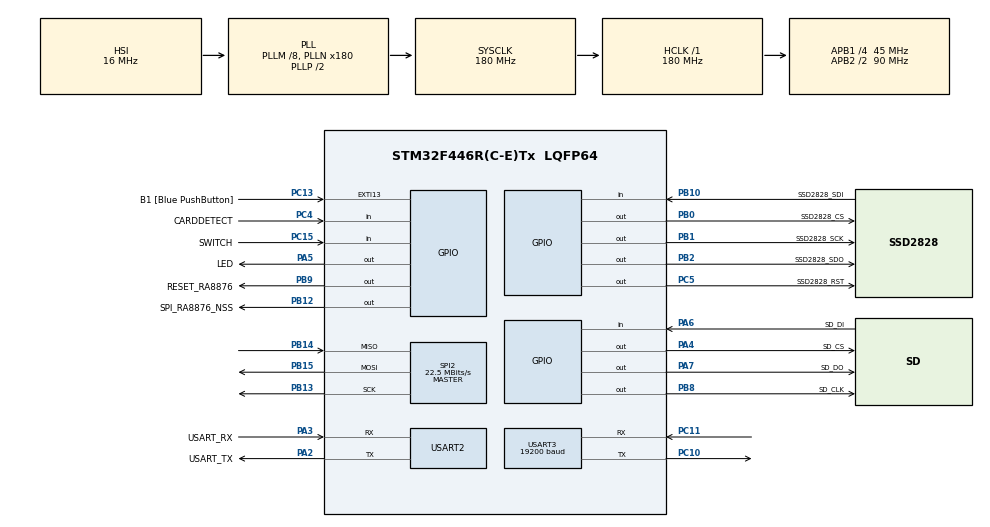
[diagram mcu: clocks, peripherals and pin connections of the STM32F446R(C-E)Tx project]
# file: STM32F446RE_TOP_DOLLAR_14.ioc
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Mcu.Family=STM32F4
Mcu.Name=STM32F446R(C-E)Tx
Mcu.Package=LQFP64
NVIC.PriorityGroup=NVIC_PRIORITYGROUP_0
NVIC.USART3_IRQn=true\:0\:0\:false\:false\:true\:true\:true\:true
PA13.GPIO_Label=TMS
PA13.Mode=Serial_Wire
PA13.Signal=SYS_JTMS-SWDIO
PA14.GPIO_Label=TCK
PA14.Mode=Serial_Wire
PA14.Signal=SYS_JTCK-SWCLK
PA2.GPIO_Label=USART_TX
PA2.Mode=Asynchronous
PA2.Signal=USART2_TX
PA3.GPIO_Label=USART_RX
PA3.Mode=Asynchronous
PA3.Signal=USART2_RX
PA4.GPIO_Label=SD_CS
PA4.Signal=GPIO_Output
PA5.GPIO_Label=LED
PA5.Signal=GPIO_Output
PA6.GPIO_Label=SD_DI
PA6.Signal=GPIO_Input
PA7.GPIO_Label=SD_DO
PA7.Signal=GPIO_Output
PB0.GPIO_Label=SSD2828_CS
PB0.Signal=GPIO_Output
PB1.GPIO_Label=SSD2828_SCK
PB1.Signal=GPIO_Output
PB10.GPIO_Label=SSD2828_SDI
PB10.Signal=GPIO_Input
PB12.GPIO_Label=SPI_RA8876_NSS
PB12.Signal=GPIO_Output
PB13.Mode=Full_Duplex_Master
PB13.Signal=SPI2_SCK
PB14.Mode=Full_Duplex_Master
PB14.Signal=SPI2_MISO
PB15.Mode=Full_Duplex_Master
PB15.Signal=SPI2_MOSI
PB2.GPIO_Label=SSD2828_SDO
PB2.Signal=GPIO_Output
PB3.GPIO_Label=SWO
PB3.Signal=SYS_JTDO-SWO
PB8.GPIO_Label=SD_CLK
PB8.GPIO_PuPd=GPIO_PULLDOWN
PB8.Signal=GPIO_Output
PB9.GPIO_Label=RESET_RA8876
PB9.Signal=GPIO_Output
PC10.Mode=Multiprocessor_communication
PC10.Signal=USART3_TX
PC11.Mode=Multiprocessor_communication
PC11.Signal=USART3_RX
PC13.GPIO_Label=B1 [Blue PushButton]
PC13.GPIO_ModeDefaultEXTI=GPIO_MODE_IT_FALLING
PC13.Signal=GPXTI13
PC15-OSC32_OUT.GPIO_Label=SWITCH
PC15-OSC32_OUT.GPIO_PuPd=GPIO_NOPULL
PC15-OSC32_OUT.Signal=GPIO_Input
PC4.GPIO_Label=CARDDETECT
PC4.GPIO_PuPd=GPIO_PULLDOWN
PC4.Signal=GPIO_Input
PC5.GPIO_Label=SSD2828_RST
PC5.Signal=GPIO_Output
PH0-OSC_IN.Mode=HSE-External-Oscillator
PH0-OSC_IN.Signal=RCC_OSC_IN
PH1-OSC_OUT.Mode=HSE-External-Oscillator
PH1-OSC_OUT.Signal=RCC_OSC_OUT
ProjectManager.HeapSize=0x200
ProjectManager.StackSize=0x400
ProjectManager.TargetToolchain=STM32CubeIDE
RCC.48MHZClocksFreq_Value=84000000
RCC.AHBFreq_Value=180000000
RCC.APB1CLKDivider=RCC_HCLK_DIV4
RCC.APB1Freq_Value=45000000
RCC.APB1TimFreq_Value=90000000
RCC.APB2CLKDivider=RCC_HCLK_DIV2
RCC.APB2Freq_Value=90000000
RCC.APB2TimFreq_Value=180000000
RCC.CortexFreq_Value=180000000
RCC.FLatency-AdvancedSettings=FLASH_LATENCY_5
RCC.HCLKFreq_Value=180000000
RCC.HSE_VALUE=8000000
RCC.HSI_VALUE=16000000
RCC.PLLM=8
RCC.PLLN=180
RCC.SYSCLKFreq_VALUE=180000000
RCC.SYSCLKSource=RCC_SYSCLKSOURCE_PLLCLK
RCC.USBFreq_Value=180000000
RCC.VCOOutputFreq_Value=360000000
SPI2.BaudRatePrescaler=SPI_BAUDRATEPRESCALER_2
SPI2.CalculateBaudRate=22.5 MBits/s
SPI2.Direction=SPI_DIRECTION_2LINES
SPI2.Mode=SPI_MODE_MASTER
SPI2.VirtualType=VM_MASTER
USART2.VirtualMode=VM_ASYNC
USART3.Address=0x0E
USART3.BaudRate=19200
USART3.VirtualMode=VM_ASYNC
USART3.WakeUpMethode=UART_WAKEUPMETHOD_ADDRESSMARK
USART3.WordLength=WORDLENGTH_9B
board=NUCLEO-F446RE

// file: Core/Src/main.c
/* USER CODE BEGIN Header */
/**
  ******************************************************************************
  * @file           : main.c
  * @brief          : Main program body
  ******************************************************************************
  * @attention
  *
  * Copyright (c) 2024 STMicroelectronics.
  * All rights reserved.
  *
  * This software is licensed under terms that can be found in the LICENSE file
  * in the root directory of this software component.
  * If no LICENSE file comes with this software, it is provided AS-IS.
  *
  *  PC15 is where switch is connected for Color / Monochrome
  *
  *  Things left to fix -
  *    * Fix scrolling on Screen0x01...
  *    DONE DONE FUCKING DONE!!!!!!!
  ******************************************************************************
  */
/* USER CODE END Header */
#include "main.h"

/* USER CODE BEGIN Includes */
#include "commands.h"
/* USER CODE END Includes */

/* USER CODE BEGIN PTD */
// here is user area
/* USER CODE END PTD */

/* USER CODE BEGIN PD */
#define SLAVE1_ADDR 0x0E			// Must set on LSB 4bits but any value in 0x00 ~ 0x0F
/* USER CODE END PD */

SPI_HandleTypeDef hspi2;

UART_HandleTypeDef huart2;
UART_HandleTypeDef huart3;

/* USER CODE BEGIN PV */
char buttonClicked;
/* USER CODE END PV */

void SystemClock_Config(void);
static void MX_GPIO_Init(void);
static void MX_USART2_UART_Init(void);
static void MX_USART3_UART_Init(void);
static void MX_SPI2_Init(void);

int main(void)
{

  /* MCU Configuration--------------------------------------------------------*/

  /* Reset of all peripherals, Initializes the Flash interface and the Systick. */
  HAL_Init();

  /* USER CODE BEGIN Init */
//  HAL_Delay(1000);

  /* USER CODE END Init */

  /* Configure the system clock */
  SystemClock_Config();

  /* Initialize all configured peripherals */
  MX_GPIO_Init();
  MX_USART2_UART_Init();
  MX_USART3_UART_Init();
  MX_SPI2_Init();
  /* USER CODE BEGIN 2 */
  InitCommands();
  /* USER CODE END 2 */

  /* Infinite loop */
  /* USER CODE BEGIN WHILE */
  while (1)
  {
	HandlePacket();
    /* USER CODE END WHILE */

  }
}

void SystemClock_Config(void)
{
  RCC_OscInitTypeDef RCC_OscInitStruct = {0};
  RCC_ClkInitTypeDef RCC_ClkInitStruct = {0};

  /** Configure the main internal regulator output voltage
  */
  __HAL_RCC_PWR_CLK_ENABLE();
  __HAL_PWR_VOLTAGESCALING_CONFIG(PWR_REGULATOR_VOLTAGE_SCALE1);

  /** Initializes the RCC Oscillators according to the specified parameters
  * in the RCC_OscInitTypeDef structure.
  */
  RCC_OscInitStruct.OscillatorType = RCC_OSCILLATORTYPE_HSI;
  RCC_OscInitStruct.HSIState = RCC_HSI_ON;
  RCC_OscInitStruct.HSICalibrationValue = RCC_HSICALIBRATION_DEFAULT;
  RCC_OscInitStruct.PLL.PLLState = RCC_PLL_ON;
  RCC_OscInitStruct.PLL.PLLSource = RCC_PLLSOURCE_HSI;
  RCC_OscInitStruct.PLL.PLLM = 8;
  RCC_OscInitStruct.PLL.PLLN = 180;
  RCC_OscInitStruct.PLL.PLLP = RCC_PLLP_DIV2;
  RCC_OscInitStruct.PLL.PLLQ = 2;
  RCC_OscInitStruct.PLL.PLLR = 2;
  if (HAL_RCC_OscConfig(&RCC_OscInitStruct) != HAL_OK)
  {
    Error_Handler();
  }

  /** Activate the Over-Drive mode
  */
  if (HAL_PWREx_EnableOverDrive() != HAL_OK)
  {
    Error_Handler();
  }

  /** Initializes the CPU, AHB and APB buses clocks
  */
  RCC_ClkInitStruct.ClockType = RCC_CLOCKTYPE_HCLK|RCC_CLOCKTYPE_SYSCLK
                              |RCC_CLOCKTYPE_PCLK1|RCC_CLOCKTYPE_PCLK2;
  RCC_ClkInitStruct.SYSCLKSource = RCC_SYSCLKSOURCE_PLLCLK;
  RCC_ClkInitStruct.AHBCLKDivider = RCC_SYSCLK_DIV1;
  RCC_ClkInitStruct.APB1CLKDivider = RCC_HCLK_DIV4;
  RCC_ClkInitStruct.APB2CLKDivider = RCC_HCLK_DIV2;

  if (HAL_RCC_ClockConfig(&RCC_ClkInitStruct, FLASH_LATENCY_5) != HAL_OK)
  {
    Error_Handler();
  }
}

static void MX_SPI2_Init(void)
{

  /* SPI2 parameter configuration*/
  hspi2.Instance = SPI2;
  hspi2.Init.Mode = SPI_MODE_MASTER;
  hspi2.Init.Direction = SPI_DIRECTION_2LINES;
  hspi2.Init.DataSize = SPI_DATASIZE_8BIT;
  hspi2.Init.CLKPolarity = SPI_POLARITY_LOW;
  hspi2.Init.CLKPhase = SPI_PHASE_1EDGE;
  hspi2.Init.NSS = SPI_NSS_SOFT;
  hspi2.Init.BaudRatePrescaler = SPI_BAUDRATEPRESCALER_2;
  hspi2.Init.FirstBit = SPI_FIRSTBIT_MSB;
  hspi2.Init.TIMode = SPI_TIMODE_DISABLE;
  hspi2.Init.CRCCalculation = SPI_CRCCALCULATION_DISABLE;
  hspi2.Init.CRCPolynomial = 10;
  if (HAL_SPI_Init(&hspi2) != HAL_OK)
  {
    Error_Handler();
  }

}

static void MX_USART2_UART_Init(void)
{

  huart2.Instance = USART2;
  huart2.Init.BaudRate = 115200;
  huart2.Init.WordLength = UART_WORDLENGTH_8B;
  huart2.Init.StopBits = UART_STOPBITS_1;
  huart2.Init.Parity = UART_PARITY_NONE;
  huart2.Init.Mode = UART_MODE_TX_RX;
  huart2.Init.HwFlowCtl = UART_HWCONTROL_NONE;
  huart2.Init.OverSampling = UART_OVERSAMPLING_16;
  if (HAL_UART_Init(&huart2) != HAL_OK)
  {
    Error_Handler();
  }

}

static void MX_USART3_UART_Init(void)
{

  huart3.Instance = USART3;
  huart3.Init.BaudRate = 19200;
  huart3.Init.WordLength = UART_WORDLENGTH_9B;
  huart3.Init.StopBits = UART_STOPBITS_1;
  huart3.Init.Parity = UART_PARITY_NONE;
  huart3.Init.Mode = UART_MODE_TX_RX;
  huart3.Init.HwFlowCtl = UART_HWCONTROL_NONE;
  huart3.Init.OverSampling = UART_OVERSAMPLING_16;
  if (HAL_MultiProcessor_Init(&huart3, 0x0E, UART_WAKEUPMETHOD_ADDRESSMARK) != HAL_OK)
  {
    Error_Handler();
  }

}

static void MX_GPIO_Init(void)
{
  GPIO_InitTypeDef GPIO_InitStruct = {0};

  /* GPIO Ports Clock Enable */
  __HAL_RCC_GPIOC_CLK_ENABLE();
  __HAL_RCC_GPIOH_CLK_ENABLE();
  __HAL_RCC_GPIOA_CLK_ENABLE();
  __HAL_RCC_GPIOB_CLK_ENABLE();

  /*Configure GPIO pin Output Level */
  HAL_GPIO_WritePin(GPIOA, SD_CS_Pin|LED_Pin|SD_DO_Pin, GPIO_PIN_RESET);

  /*Configure GPIO pin Output Level */
  HAL_GPIO_WritePin(SSD2828_RST_GPIO_Port, SSD2828_RST_Pin, GPIO_PIN_RESET);

  /*Configure GPIO pin Output Level */
  HAL_GPIO_WritePin(GPIOB, SSD2828_CS_Pin|SSD2828_SCK_Pin|SSD2828_SDO_Pin|SPI_RA8876_NSS_Pin
                          |SD_CLK_Pin|RESET_RA8876_Pin, GPIO_PIN_RESET);

  /*Configure GPIO pin : B1_Pin */
  GPIO_InitStruct.Pin = B1_Pin;
  GPIO_InitStruct.Mode = GPIO_MODE_IT_FALLING;
  GPIO_InitStruct.Pull = GPIO_NOPULL;
  HAL_GPIO_Init(B1_GPIO_Port, &GPIO_InitStruct);

  /*Configure GPIO pin : SWITCH_Pin */
  GPIO_InitStruct.Pin = SWITCH_Pin;
  GPIO_InitStruct.Mode = GPIO_MODE_INPUT;
  GPIO_InitStruct.Pull = GPIO_NOPULL;
  HAL_GPIO_Init(SWITCH_GPIO_Port, &GPIO_InitStruct);

  /*Configure GPIO pins : SD_CS_Pin LED_Pin SD_DO_Pin */
  GPIO_InitStruct.Pin = SD_CS_Pin|LED_Pin|SD_DO_Pin;
  GPIO_InitStruct.Mode = GPIO_MODE_OUTPUT_PP;
  GPIO_InitStruct.Pull = GPIO_NOPULL;
  GPIO_InitStruct.Speed = GPIO_SPEED_FREQ_LOW;
  HAL_GPIO_Init(GPIOA, &GPIO_InitStruct);

  /*Configure GPIO pin : SD_DI_Pin */
  GPIO_InitStruct.Pin = SD_DI_Pin;
  GPIO_InitStruct.Mode = GPIO_MODE_INPUT;
  GPIO_InitStruct.Pull = GPIO_NOPULL;
  HAL_GPIO_Init(SD_DI_GPIO_Port, &GPIO_InitStruct);

  /*Configure GPIO pin : CARDDETECT_Pin */
  GPIO_InitStruct.Pin = CARDDETECT_Pin;
  GPIO_InitStruct.Mode = GPIO_MODE_INPUT;
  GPIO_InitStruct.Pull = GPIO_PULLDOWN;
  HAL_GPIO_Init(CARDDETECT_GPIO_Port, &GPIO_InitStruct);

  /*Configure GPIO pin : SSD2828_RST_Pin */
  GPIO_InitStruct.Pin = SSD2828_RST_Pin;
  GPIO_InitStruct.Mode = GPIO_MODE_OUTPUT_PP;
  GPIO_InitStruct.Pull = GPIO_NOPULL;
  GPIO_InitStruct.Speed = GPIO_SPEED_FREQ_LOW;
  HAL_GPIO_Init(SSD2828_RST_GPIO_Port, &GPIO_InitStruct);

  /*Configure GPIO pins : SSD2828_CS_Pin SSD2828_SCK_Pin SSD2828_SDO_Pin SPI_RA8876_NSS_Pin
                           RESET_RA8876_Pin */
  GPIO_InitStruct.Pin = SSD2828_CS_Pin|SSD2828_SCK_Pin|SSD2828_SDO_Pin|SPI_RA8876_NSS_Pin
                          |RESET_RA8876_Pin;
  GPIO_InitStruct.Mode = GPIO_MODE_OUTPUT_PP;
  GPIO_InitStruct.Pull = GPIO_NOPULL;
  GPIO_InitStruct.Speed = GPIO_SPEED_FREQ_LOW;
  HAL_GPIO_Init(GPIOB, &GPIO_InitStruct);

  /*Configure GPIO pin : SSD2828_SDI_Pin */
  GPIO_InitStruct.Pin = SSD2828_SDI_Pin;
  GPIO_InitStruct.Mode = GPIO_MODE_INPUT;
  GPIO_InitStruct.Pull = GPIO_NOPULL;
  HAL_GPIO_Init(SSD2828_SDI_GPIO_Port, &GPIO_InitStruct);

  /*Configure GPIO pin : SD_CLK_Pin */
  GPIO_InitStruct.Pin = SD_CLK_Pin;
  GPIO_InitStruct.Mode = GPIO_MODE_OUTPUT_PP;
  GPIO_InitStruct.Pull = GPIO_PULLDOWN;
  GPIO_InitStruct.Speed = GPIO_SPEED_FREQ_LOW;
  HAL_GPIO_Init(SD_CLK_GPIO_Port, &GPIO_InitStruct);

}

/* USER CODE BEGIN 4 */
void HAL_GPIO_EXTI_Callback(uint16_t GPIO_Pin)
{
  /* Prevent unused argument(s) compilation warning */
  if(GPIO_Pin == B1_Pin)
  {
	  buttonClicked = 1;
  }
  /* NOTE: This function Should not be modified, when the callback is needed,
           the HAL_GPIO_EXTI_Callback could be implemented in the user file
   */
}

void HAL_UART_RxCpltCallback(UART_HandleTypeDef *UartHandle)
{
	PacketProc();
}
/* USER CODE END 4 */

void Error_Handler(void)
{
  __disable_irq();
  while (1)
  {
  }
}
